VERSION "HIPBNYYYYYYYYYYYYYYYYYYYYYYYYYYYYYYYYYYYYY/4/%%%/4/'%**4YYY///"

NS_ :

BS_:

BU_: External BoR

BO_ 3221225472 VECTOR__INDEPENDENT_SIG_MSG: 0 Vector__XXX
 SG_ fcm_LOAD_CONTROL : 0|16@1+ (0.01,0) [0|655.35] "A" Vector__XXX

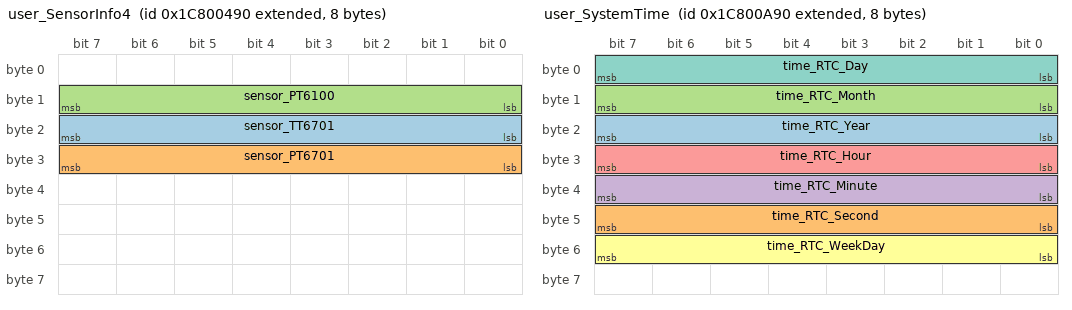
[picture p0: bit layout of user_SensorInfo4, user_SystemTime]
BO_ 2625635472 user_SensorInfo4: 8 BoR
 SG_ sensor_TT6701 : 16|8@1+ (1,-40) [-40|215] "degC"  External
 SG_ sensor_PT6701 : 24|8@1+ (0.01,0) [0|2.55] "barg"  External
 SG_ sensor_PT6100 : 8|8@1+ (0.1,0) [0|25.5] "barg"  External

BO_ 2625650320 user_ALSH_B04: 8 BoR
 SG_ info_ALSH_B04_Latched : 32|32@1+ (1,0) [0|4294967295] ""  External
 SG_ info_ALSH_B04_Active : 0|32@1+ (1,0) [0|4294967295] ""  External

BO_ 2625646224 user_ALSH_B03: 8 BoR
 SG_ info_ALSH_B03_Latched : 32|32@1+ (1,0) [0|4294967295] ""  External
 SG_ info_ALSH_B03_Active : 0|32@1+ (1,0) [0|4294967295] ""  External

BO_ 2625642128 user_ALSH_B02: 8 BoR
 SG_ info_ALSH_B02_Latched : 32|32@1+ (1,0) [0|4294967295] ""  External
 SG_ info_ALSH_B02_Active : 0|32@1+ (1,0) [0|4294967295] ""  External

BO_ 2625642384 user_WARN_B06: 8 BoR
 SG_ info_WARN_B06_Latched : 32|32@1+ (1,0) [0|4294967295] ""  External
 SG_ info_WARN_B06_Active : 0|32@1+ (1,0) [0|4294967295] ""  External

BO_ 2625637008 user_SystemTime: 8 BoR
 SG_ time_RTC_Year : 16|8@1+ (1,0) [0|255] ""  External
 SG_ time_RTC_Second : 40|8@1+ (1,0) [0|255] ""  External
 SG_ time_RTC_Month : 8|8@1+ (1,0) [0|255] ""  External
 SG_ time_RTC_Minute : 32|8@1+ (1,0) [0|255] ""  External
 SG_ time_RTC_Hour : 24|8@1+ (1,0) [0|255] ""  External
 SG_ time_RTC_WeekDay : 48|8@1+ (1,0) [0|255] ""  External
 SG_ time_RTC_Day : 0|8@1+ (1,0) [0|255] ""  External

BO_ 2625638288 user_WARN: 8 BoR
 SG_ info_WARN_Latched : 32|32@1+ (1,0) [0|4294967295] ""  External
 SG_ info_WARN_Active : 0|32@1+ (1,0) [0|4294967295] ""  External

BO_ 2625638032 user_ALSH: 8 BoR
 SG_ info_ALSH_Latched : 32|32@1+ (1,0) [0|4294967295] ""  External,BoR
 SG_ info_ALSH_Active : 0|32@1+ (1,0) [0|4294967295] ""  External,BoR

BO_ 2625637776 user_ALST: 8 BoR
 SG_ info_ALST_Latched : 32|32@1+ (1,0) [0|4294967295] ""  External,BoR
 SG_ info_ALST_Active : 0|32@1+ (1,0) [0|4294967295] ""  External,BoR

BO_ 2625636752 user_SystemInfo2: 8 BoR
 SG_ info_SystemTotalPower : 32|32@1+ (0.01,0) [0|42949672.95] "kWh"  External
 SG_ info_SystemRuntime : 0|32@1+ (0.1,0) [0|429496729.5] "h"  External

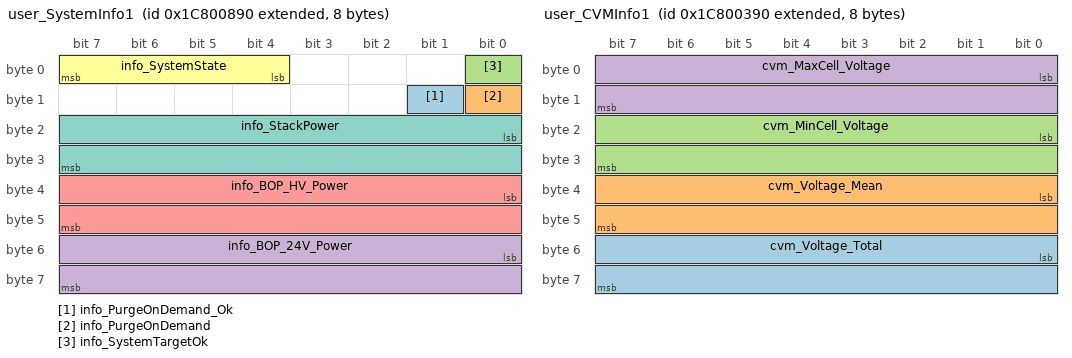
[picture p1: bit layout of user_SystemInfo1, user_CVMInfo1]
BO_ 2625636496 user_SystemInfo1: 8 BoR
 SG_ info_PurgeOnDemand_Ok : 9|1@1+ (1,0) [0|1] ""  External
 SG_ info_PurgeOnDemand : 8|1@1+ (1,0) [0|1] ""  External
 SG_ info_SystemTargetOk : 0|1@1+ (1,0) [0|1] "" Vector__XXX
 SG_ info_BOP_24V_Power : 48|16@1+ (0.01,0) [0|655.35] "kW"  External
 SG_ info_BOP_HV_Power : 32|16@1+ (0.01,0) [0|655.35] "kW"  External
 SG_ info_SystemState : 4|4@1+ (1,0) [0|15] ""  External
 SG_ info_StackPower : 16|16@1+ (0.01,0) [0|655.35] "kW"  External

BO_ 2625635216 user_CVMInfo1: 8 BoR
 SG_ cvm_Voltage_Total : 48|16@1+ (0.1,0) [0|6553.5] "V"  External
 SG_ cvm_Voltage_Mean : 32|16@1+ (0.001,0) [0|65.535] "V"  External
 SG_ cvm_MinCell_Voltage : 16|16@1+ (0.001,0) [0|65.535] "V"  External
 SG_ cvm_MaxCell_Voltage : 0|16@1+ (0.001,0) [0|65.535] "V"  External

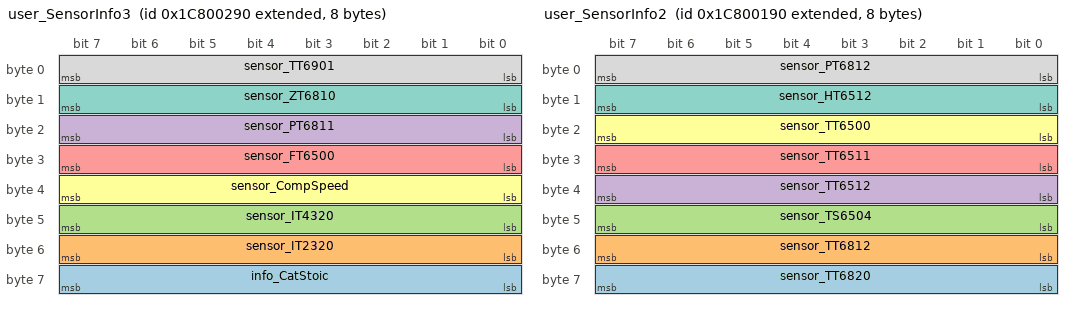
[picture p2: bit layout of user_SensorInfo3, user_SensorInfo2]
BO_ 2625634960 user_SensorInfo3: 8 BoR
 SG_ info_CatStoic : 56|8@1+ (0.01,0.5) [0.5|3.05] ""  External
 SG_ sensor_IT2320 : 48|8@1+ (0.5,0) [0|127.5] "A"  External
 SG_ sensor_IT4320 : 40|8@1+ (2,0) [0|510] "A"  External
 SG_ sensor_PT6811 : 16|8@1+ (0.01,0) [0|2.55] "barg"  External
 SG_ sensor_FT6500 : 24|8@1+ (1,0) [0|255] "g/s"  External
 SG_ sensor_CompSpeed : 32|8@1+ (500,0) [0|127500] "rpm"  External
 SG_ sensor_ZT6810 : 8|8@1+ (0.5,0) [0|127.5] "%"  External
 SG_ sensor_TT6901 : 0|8@1+ (1,-40) [-40|215] "degC"  External

BO_ 2625634704 user_SensorInfo2: 8 BoR
 SG_ sensor_TT6820 : 56|8@1+ (1,-40) [-40|215] "degC"  External
 SG_ sensor_TT6812 : 48|8@1+ (1,-40) [-40|215] "degC"  External
 SG_ sensor_TS6504 : 40|8@1+ (1,-40) [-40|215] "degC"  External
 SG_ sensor_TT6512 : 32|8@1+ (1,-40) [-40|215] "degC"  External
 SG_ sensor_TT6511 : 24|8@1+ (1,-40) [-40|215] "degC"  External
 SG_ sensor_TT6500 : 16|8@1+ (1,-40) [-40|215] "degC"  External
 SG_ sensor_HT6512 : 8|8@1+ (0.5,0) [0|127.5] "%"  External
 SG_ sensor_PT6812 : 0|8@1+ (0.01,0) [0|2.55] "barg"  External

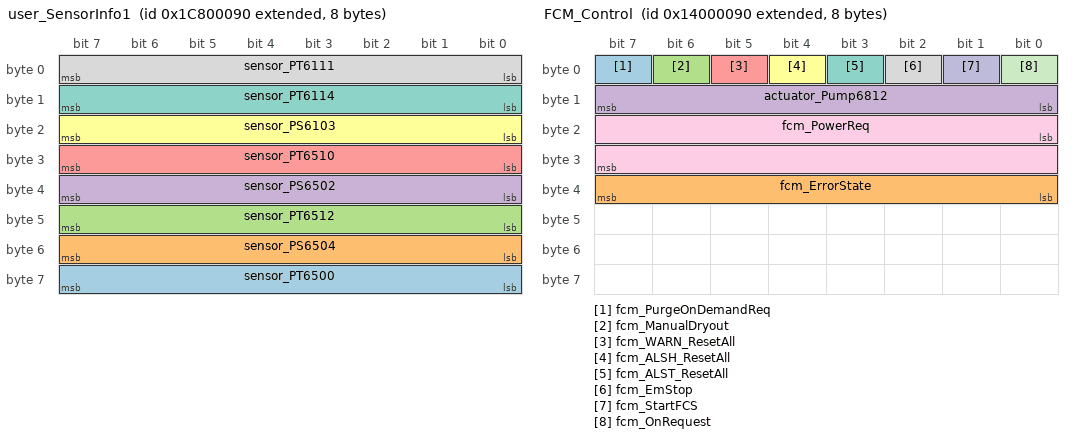
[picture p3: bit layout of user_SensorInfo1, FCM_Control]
BO_ 2625634448 user_SensorInfo1: 8 BoR
 SG_ sensor_PT6500 : 56|8@1+ (0.01,-1) [-1|1.55] "barg"  External
 SG_ sensor_PS6504 : 48|8@1+ (0.01,0) [0|2.55] "barg"  External
 SG_ sensor_PT6512 : 40|8@1+ (0.01,0) [0|2.55] "barg"  External
 SG_ sensor_PS6502 : 32|8@1+ (0.01,0) [0|2.55] "barg"  External
 SG_ sensor_PT6510 : 24|8@1+ (0.01,0) [0|2.55] "barg"  External
 SG_ sensor_PS6103 : 16|8@1+ (0.01,-1) [-1|1.55] "barg"  External
 SG_ sensor_PT6114 : 8|8@1+ (0.01,-1) [-1|1.55] "barg"  External
 SG_ sensor_PT6111 : 0|8@1+ (0.01,0) [0|2.55] "barg"  External

BO_ 2491416720 Load_Info: 8 BoR
 SG_ load_ActualCurrent : 0|16@1+ (0.01,0) [0|655.35] "A"  External

BO_ 2483028112 FCM_Control: 8 External
 SG_ fcm_PurgeOnDemandReq : 7|1@1+ (1,0) [0|1] ""  BoR
 SG_ fcm_ErrorState : 32|8@1+ (1,0) [0|255] ""  BoR
 SG_ fcm_ManualDryout : 6|1@1+ (1,0) [0|1] ""  BoR
 SG_ actuator_Pump6812 : 8|8@1+ (1,0) [0|255] "%"  BoR
 SG_ fcm_WARN_ResetAll : 5|1@1+ (1,0) [0|1] ""  BoR
 SG_ fcm_ALSH_ResetAll : 4|1@1+ (1,0) [0|1] ""  BoR
 SG_ fcm_ALST_ResetAll : 3|1@1+ (1,0) [0|1] ""  BoR
 SG_ fcm_EmStop : 2|1@1+ (1,0) [0|1] ""  BoR
 SG_ fcm_PowerReq : 16|16@1+ (10,0) [0|655350] "W"  BoR
 SG_ fcm_StartFCS : 1|1@1+ (1,0) [0|1] ""  BoR
 SG_ fcm_OnRequest : 0|1@1+ (1,0) [0|1] ""  BoR

CM_ BO_ 3221225472 "This is a message for not used signals, created by Vector CANdb++ DBC OLE DB Provider.";
BA_DEF_  "Manufacturer" STRING ;
BA_DEF_  "BusType" STRING ;
BA_DEF_  "NmType" STRING ;
BA_DEF_  "NmAsrBaseAddress" HEX 0 536870911;
BA_DEF_  "ProtocolType" STRING ;
BA_DEF_ BO_  "GenMsgSendType" ENUM  "cyclic","reserved","cyclicIfActive","ManualTrig","OnChange","reserved","reserved","reserved","noMsgSendType";
BA_DEF_ BO_  "GenMsgCycleTime" INT 0 3600000;
BA_DEF_ BO_  "GenMsgRequestable" INT 0 1;
BA_DEF_ BO_  "SingleFrame" INT 0 1;
BA_DEF_ BO_  "VFrameFormat" ENUM  "StandardCAN","ExtendedCAN","reserved","J1939PG";
BA_DEF_ BO_  "GenMsgILSupport" ENUM  "No","Yes";
BA_DEF_ BO_  "VPEnabled" ENUM  "FALSE","TRUE";
BA_DEF_ SG_  "GenSigStartValue" INT 0 10000;
BA_DEF_ SG_  "GenSigTimeoutTime" INT 0 1000000;
BA_DEF_ SG_  "GenSigILSupport" ENUM  "No","Yes";
BA_DEF_ SG_  "GenSigEVName" STRING ;
BA_DEF_ SG_  "GenSigSendType" ENUM  "cyclic","OnWrite","OnWriteWithRepetition","OnChange","OnChangeWithRepetition","IfActive","IfActiveWithRepetition","NoSigSendType";
BA_DEF_ SG_  "VPRWFunction" ENUM  "Read","Write","Publish","Trigger";
BA_DEF_ BU_  "NmStationAddress" HEX 0 253;
BA_DEF_  "NmAsrWaitBusSleepTime" INT 0 65535;
BA_DEF_  "NmAsrTimeoutTime" INT 0 65535;
BA_DEF_  "NmAsrRepeatMessageTime" INT 0 65535;
BA_DEF_ BU_  "NmAsrNode" ENUM  "No","Yes";
BA_DEF_  "NmAsrMessageCount" INT 1 256;
BA_DEF_ BU_  "NmAsrCanMsgReducedTime" INT 0 65535;
BA_DEF_  "NmAsrCanMsgCycleTime" INT 0 65535;
BA_DEF_ BU_  "ILUsed" ENUM  "No","Yes";
BA_DEF_ BO_  "CanTpSTmin" INT 0 255;
BA_DEF_ BO_  "CanTpFcFrameId" HEX 0 2147483647;
BA_DEF_ BU_  "ECU" STRING ;
BA_DEF_DEF_  "Manufacturer" "VOLVO_AB";
BA_DEF_DEF_  "BusType" "CAN";
BA_DEF_DEF_  "NmType" "";
BA_DEF_DEF_  "NmAsrBaseAddress" 419397632;
BA_DEF_DEF_  "ProtocolType" "";
BA_DEF_DEF_  "GenMsgSendType" "noMsgSendType";
BA_DEF_DEF_  "GenMsgCycleTime" 0;
BA_DEF_DEF_  "GenMsgRequestable" 1;
BA_DEF_DEF_  "SingleFrame" 1;
BA_DEF_DEF_  "VFrameFormat" "J1939PG";
BA_DEF_DEF_  "GenMsgILSupport" "Yes";
BA_DEF_DEF_  "VPEnabled" "TRUE";
BA_DEF_DEF_  "GenSigStartValue" 0;
BA_DEF_DEF_  "GenSigTimeoutTime" 0;
BA_DEF_DEF_  "GenSigILSupport" "Yes";
BA_DEF_DEF_  "GenSigEVName" "Env@Nodename_@Signame";
BA_DEF_DEF_  "GenSigSendType" "NoSigSendType";
BA_DEF_DEF_  "VPRWFunction" "Read";
BA_DEF_DEF_  "NmStationAddress" 0;
BA_DEF_DEF_  "NmAsrWaitBusSleepTime" 750;
BA_DEF_DEF_  "NmAsrTimeoutTime" 1000;
BA_DEF_DEF_  "NmAsrRepeatMessageTime" 800;
BA_DEF_DEF_  "NmAsrNode" "Yes";
BA_DEF_DEF_  "NmAsrMessageCount" 64;
BA_DEF_DEF_  "NmAsrCanMsgReducedTime" 50;
BA_DEF_DEF_  "NmAsrCanMsgCycleTime" 200;
BA_DEF_DEF_  "ILUsed" "Yes";
BA_DEF_DEF_  "CanTpSTmin" 1;
BA_DEF_DEF_  "CanTpFcFrameId" 2147483647;
BA_DEF_DEF_  "ECU" "APU Control Unit";
BA_ "NmAsrBaseAddress" 0;
BA_ "NmType" "NmAsr";
BA_ "ProtocolType" "J1939";
BA_ "Manufacturer" "PowerCell_AB";
BA_ "VFrameFormat" BO_ 2625635472 1;
BA_ "GenMsgCycleTime" BO_ 2625635472 250;
BA_ "GenMsgSendType" BO_ 2625635472 0;
BA_ "VFrameFormat" BO_ 2625650320 1;
BA_ "GenMsgCycleTime" BO_ 2625650320 500;
BA_ "GenMsgSendType" BO_ 2625650320 0;
BA_ "VFrameFormat" BO_ 2625646224 1;
BA_ "GenMsgCycleTime" BO_ 2625646224 500;
BA_ "GenMsgSendType" BO_ 2625646224 0;
BA_ "VFrameFormat" BO_ 2625642128 1;
BA_ "GenMsgCycleTime" BO_ 2625642128 500;
BA_ "GenMsgSendType" BO_ 2625642128 0;
BA_ "VFrameFormat" BO_ 2625642384 1;
BA_ "GenMsgCycleTime" BO_ 2625642384 500;
BA_ "GenMsgSendType" BO_ 2625642384 0;
BA_ "VFrameFormat" BO_ 2625637008 1;
BA_ "GenMsgCycleTime" BO_ 2625637008 1000;
BA_ "GenMsgSendType" BO_ 2625637008 0;
BA_ "VFrameFormat" BO_ 2625638288 1;
BA_ "GenMsgCycleTime" BO_ 2625638288 500;
BA_ "GenMsgSendType" BO_ 2625638288 0;
BA_ "VFrameFormat" BO_ 2625638032 1;
BA_ "GenMsgCycleTime" BO_ 2625638032 500;
BA_ "GenMsgSendType" BO_ 2625638032 0;
BA_ "VFrameFormat" BO_ 2625637776 1;
BA_ "GenMsgCycleTime" BO_ 2625637776 500;
BA_ "GenMsgSendType" BO_ 2625637776 0;
BA_ "VFrameFormat" BO_ 2625636752 1;
BA_ "GenMsgCycleTime" BO_ 2625636752 10000;
BA_ "GenMsgSendType" BO_ 2625636752 0;
BA_ "VFrameFormat" BO_ 2625636496 1;
BA_ "GenMsgCycleTime" BO_ 2625636496 250;
BA_ "GenMsgSendType" BO_ 2625636496 0;
BA_ "VFrameFormat" BO_ 2625635216 1;
BA_ "GenMsgCycleTime" BO_ 2625635216 100;
BA_ "GenMsgSendType" BO_ 2625635216 0;
BA_ "VFrameFormat" BO_ 2625634960 1;
BA_ "GenMsgCycleTime" BO_ 2625634960 250;
BA_ "GenMsgSendType" BO_ 2625634960 0;
BA_ "VFrameFormat" BO_ 2625634704 1;
BA_ "GenMsgCycleTime" BO_ 2625634704 250;
BA_ "GenMsgSendType" BO_ 2625634704 0;
BA_ "GenMsgCycleTime" BO_ 2625634448 250;
BA_ "GenMsgSendType" BO_ 2625634448 0;
BA_ "VFrameFormat" BO_ 2625634448 1;
BA_ "GenMsgCycleTime" BO_ 2491416720 20;
BA_ "GenMsgSendType" BO_ 2491416720 0;
BA_ "VFrameFormat" BO_ 2491416720 1;
BA_ "GenMsgCycleTime" BO_ 2483028112 100;
BA_ "GenMsgSendType" BO_ 2483028112 0;
BA_ "VFrameFormat" BO_ 2483028112 1;
BA_ "GenSigStartValue" SG_ 2625634448 sensor_PT6500 100;
BA_ "GenSigStartValue" SG_ 2625634448 sensor_PS6103 100;
BA_ "GenSigStartValue" SG_ 2625634448 sensor_PT6114 100;
BA_ "GenSigTimeoutTime" SG_ 2483028112 fcm_PurgeOnDemandReq 500;
BA_ "GenSigTimeoutTime" SG_ 2483028112 fcm_ManualDryout 500;
BA_ "GenSigTimeoutTime" SG_ 2483028112 fcm_OnRequest 500;
